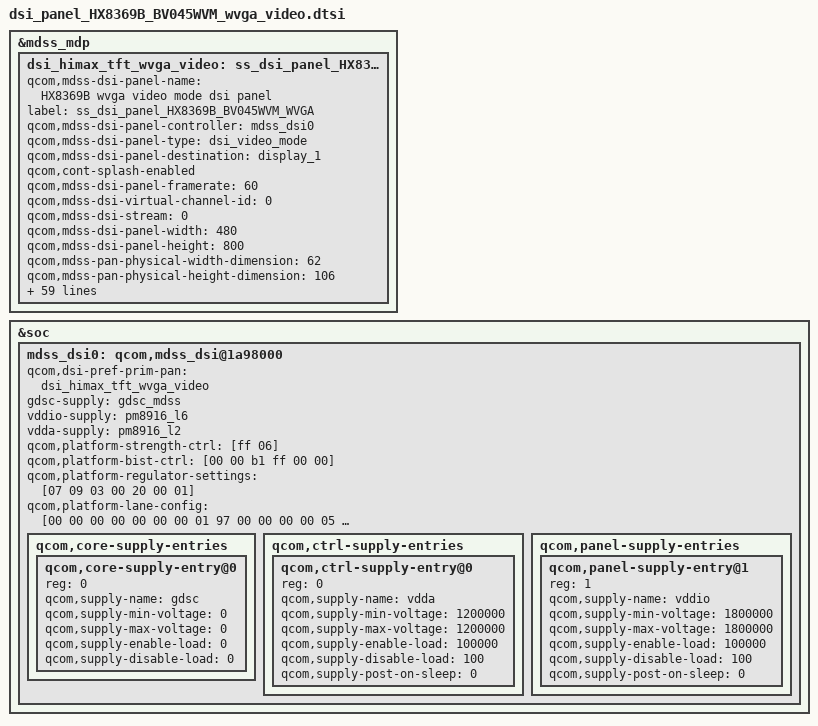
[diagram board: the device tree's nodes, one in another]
/* Copyright (c) 2013-14, Samsung Electronics Corporation. All rights reserved.
 *
 * This program is free software; you can redistribute it and/or modify
 * it under the terms of the GNU General Public License version 2 and
 * only version 2 as published by the Free Software Foundation.
 *
 * This program is distributed in the hope that it will be useful,
 * but WITHOUT ANY WARRANTY; without even the implied warranty of
 * MERCHANTABILITY or FITNESS FOR A PARTICULAR PURPOSE.  See the
 * GNU General Public License for more details.
 */

/*---------------------------------------------------------------------------
 * This file is autogenerated file using gcdb parser. Please do not edit it.
 * Update input XML file to add a new entry or update variable in this file
 * VERSION = "1.0"
 *---------------------------------------------------------------------------*/
&mdss_mdp {
	dsi_himax_tft_wvga_video: ss_dsi_panel_HX8369B_BV045WVM_WVGA/*qcom,mdss_dsi_hx8369b_wvga_video*/ {
		qcom,mdss-dsi-panel-name = "HX8369B wvga video mode dsi panel";
		label = "ss_dsi_panel_HX8369B_BV045WVM_WVGA";
		qcom,mdss-dsi-panel-controller = <&mdss_dsi0>;
		qcom,mdss-dsi-panel-type = "dsi_video_mode";
		qcom,mdss-dsi-panel-destination = "display_1";
		qcom,cont-splash-enabled;
		qcom,mdss-dsi-panel-framerate = <60>;
		qcom,mdss-dsi-virtual-channel-id = <0>;
		qcom,mdss-dsi-stream = <0>;
		qcom,mdss-dsi-panel-width = <480>;
		qcom,mdss-dsi-panel-height = <800>;
		qcom,mdss-pan-physical-width-dimension = <62>; /* <Width> real size of panel in mm */
		qcom,mdss-pan-physical-height-dimension = <106>; /*<Height> real size of panel in mm */
		qcom,mdss-dsi-lp11-init;
		qcom,mdss-dsi-init-delay-us = <100>;
		qcom,mdss-dsi-h-front-porch = <110>;
		qcom,mdss-dsi-h-back-porch = <110>;
		qcom,mdss-dsi-h-pulse-width = <4>;
		qcom,mdss-dsi-h-sync-skew = <0>;
		qcom,mdss-dsi-v-back-porch = <12>;
		qcom,mdss-dsi-v-front-porch = <10>;
		qcom,mdss-dsi-v-pulse-width = <4>;
		qcom,mdss-dsi-h-left-border = <0>;
		qcom,mdss-dsi-h-right-border = <0>;
		qcom,mdss-dsi-v-top-border = <0>;
		qcom,mdss-dsi-v-bottom-border = <0>;
		qcom,mdss-dsi-bpp = <24>;
		qcom,mdss-dsi-color-order = <0>;
		qcom,mdss-dsi-underflow-color = <0xff>;
		qcom,mdss-dsi-border-color = <0>;
		qcom,mdss-dsi-dma-trigger = "trigger_sw";
		qcom,mdss-dsi-mdp-trigger = "none";
		qcom,mdss-dsi-bl-min-level = <1>;
		qcom,mdss-dsi-bl-max-level = <255>;
		qcom,mdss-dsi-bl-pmic-control-type = "bl_ctrl_dcs";
		qcom,mdss-dsi-lane-0-state;
		qcom,mdss-dsi-lane-1-state;
		qcom,mdss-dsi-bllp-eof-power-mode;
		qcom,mdss-dsi-bllp-power-mode;
		qcom,mdss-dsi-traffic-mode = "burst_mode";
		qcom,mdss-force-clk-lane-hs = <0>;
		qcom,mdss-dsi-reset-sequence = <1 20>, <0 1>, <1 20>;
		qcom,mdss-dsi-h-sync-pulse = <0>;
		qcom,mdss-dsi-panel-timings = [51 14 0C 00 36 38 12 18 1B 03 04 00];
		qcom,mdss-dsi-t-clk-pre = <0x15>;
		qcom,mdss-dsi-t-clk-post = <0x04>;
		qcom,mdss-dsi-on-command = [
					/* < Power Setting Sequence(1) > */
					39 01 00 00 00 00 04 B9 FF 83 69
					39 01 00 00 00 00 0B B1 0B 83 77 00 0F 0F 0B 0B 0C 0A
					39 01 00 00 00 00 04 C6 41 FF 7D
					39 01 00 00 00 00 05 E3 00 00 00 00
					39 01 00 00 00 00 07 C0 73 50 00 34 C4 00
					/* < Power Setting Sequence(2) > */
					39 01 00 00 00 00 10 BA 31 00 16 CA B1 0A 00 10 28 02 21 21 9A 1A 8F
					39 01 00 00 00 00 02 3A 70
					39 01 00 00 00 00 05 B3 83 00 31 03
					39 01 00 00 00 00 02 B4 00
					39 01 00 00 00 00 02 CC 0E
					39 01 00 00 00 00 02 EA 72
					39 01 00 00 00 00 02 B2 03
					39 01 00 00 00 00 5D D5 00 00 07 00 09 00 00 10 01 00 00 00 01 42 37
										 00 00 08 2A 08 47 00 00 03 00 00 00 00 00 00 00
										 00 00 00 00 15 00 00 98 98 44 66 00 22 51 00 00
										 89 98 33 11 77 55 04 00 00 98 98 55 77 11 33 40
										 00 00 89 98 22 00 66 44 15 00 00 00 01 00 00 00
										 03 00 0F FF FF 03 00 0F FF FF 00 8C 5A
					/* < Gamma Setting Sequence(3) > */
					39 01 00 00 00 00 24 E0 01 02 05 2C 33 3F 10 33 06 0D 0E 10 16 10 14
										 13 19 01 02 05 2C 32 3F 0E 30 08 0E 0F 12 11 14
										 12 13 19 01
					/* < Display on Sequence> */
					39 01 00 00 00 00 03 C9 0F 01
					39 01 00 00 00 00 02 55 00
					39 01 00 00 00 00 02 53 24
					05 01 00 00 78 00 02 11 00
					05 01 00 00 0A 00 02 29 00
					];
		qcom,mdss-dsi-on-command-state = "dsi_lp_mode";
		qcom,mdss-dsi-off-command-state = "dsi_hs_mode";
		qcom,mdss-dsi-off-command = [39 01 00 00 46 00 02 28 00
					39 01 00 00 46 00 02 10 00];
		samsung,tft-common-support;
		samsung,panel-vendor = "BOE";
		samsung,mdss-dsi-bl-scale-low-level = <8>;
		samsung,mdss-dsi-bl-scale-dim-level = <8>;
		samsung,mdss-dsi-bl-scale-default-level = <89>;
		samsung,mdss-dsi-bl-scale-max-level = <188>;
		samsung,mdss-dsi-bl-pms-low-level = <7>;
		samsung,mdss-dsi-bl-pms-dim-level = <7>;
		samsung,mdss-dsi-bl-pms-default-level = <158>;
		samsung,mdss-dsi-bl-pms-max-level = <255>;
		samsung,tft_pwm_tx_cmds_revA=[
			39 01 00 00 00 00 02 51 FF/*First command should be PWM duty change command*/
		];
		samsung,cabc_on_tx_cmds_revA = [
			39 01 00 00 00 00 02 55 01
		];
		samsung,cabc_off_tx_cmds_revA = [
			39 01 00 00 00 00 02 55 00
		];
		/*
		* ************************************************************************************************************************
		* Scaled level to index mappings
		* ************************************************************************************************************************
		*/
		samsung,scaled_level_map_table_revA = <
		/*<idx>	  <from>  <till> <scaled_level> */
			0		0		7		6
			1		8		9		7
			2		10		12		8
			3		13		14		9
			4		15		17		10
			5		18		19		11
			6		20		22		12
			7		23		24		13
			8		25		27		14
			9		28		29		15
			10		30		32		16
			11		33		34		17
			12		35		37		18
			13		38		39		19
			14		40		42		20
			15		43		44		21
			16		45		47		22
			17		48		49		23
			18		50		52		24
			19		53		54		25
			20		55		57		26
			21		58		59		27
			22		60		62		28
			23		63		64		29
			24		65		67		30
			25		68		70		31
			26		71		72		32
			27		73		75		33
			28		76		77		34
			29		78		80		35
			30		81		82		36
			31		83		85		37
			32		86		87		38
			33		88		90		39
			34		91		92		41
			35		93		95		43
			36		96		97		45
			37		98		100		47
			38		101		102		49
			39		103		105		51
			40		106		107		53
			41		108		110		55
			42		111		112		57
			43		113		115		59
			44		116		117		61
			45		118		120		63
			46		121		122		65
			47		123		125		67
			48		126		127		69
			49		128		130		71
			50		131		133		73
			51		134		135		75
			52		136		138		77
			53		139		140		79
			54		141		143		81
			55		144		145		83
			56		146		148		85
			57		149		150		87
			58		151		153		89
			59		154		155		91
			60		156		158		93
			61		159		160		95
			62		161		163		98
			63		164		165		101
			64		166		168		104
			65		169		170		107
			66		171		173		110
			67		174		175		113
			68		176		178		116
			69		179		180		119
			70		181		183		122
			71		184		185		125
			72		186		188		128
			72		189		190		131
			74		191		193		134
			75		194		196		137
			76		197		198		140
			77		199		201		143
			78		202		203		146
			79		204		206		149
			80		207		208		152
			81		209		211		155
			82		212		213		158
			83		214		216		161
			84		217		218		164
			85		219		221		167
			86		222		223		170
			87		224		226		173
			88		227		228		176
			89		229		231		179
			90		232		233		182
			91		234		236		185
			92		237		238		188
			93		239		241		191
			94		242		243		195
			95		244		246		199
			96		247		248		202
			97		249		251		205
			98		252		253		208
			99		254		255		210
		>;
	};
};
&soc {
	mdss_dsi0: qcom,mdss_dsi@1a98000 {
		qcom,dsi-pref-prim-pan = <&dsi_himax_tft_wvga_video>;
		gdsc-supply = <&gdsc_mdss>;
		vddio-supply = <&pm8916_l6>;
		vdda-supply = <&pm8916_l2>;
		qcom,platform-strength-ctrl = [ff 06];
		qcom,platform-bist-ctrl = [00 00 b1 ff 00 00];
		qcom,platform-regulator-settings = [07 09 03 00 20 00 01];
		qcom,platform-lane-config = [00 00 00 00 00 00 00 01 97
			00 00 00 00 05 00 00 01 97
			00 00 00 00 0a 00 00 01 97
			00 00 00 00 0f 00 00 01 97
			00 c0 00 00 00 00 00 01 bb];
		qcom,core-supply-entries {
			#address-cells = <1>;
			#size-cells = <0>;

			qcom,core-supply-entry@0 {
				reg = <0>;
				qcom,supply-name = "gdsc";
				qcom,supply-min-voltage = <0>;
				qcom,supply-max-voltage = <0>;
				qcom,supply-enable-load = <0>;
				qcom,supply-disable-load = <0>;
			};
		};
		qcom,ctrl-supply-entries {
			#address-cells = <1>;
			#size-cells = <0>;

			qcom,ctrl-supply-entry@0 {
				reg = <0>;
				qcom,supply-name = "vdda";
				qcom,supply-min-voltage = <1200000>;
				qcom,supply-max-voltage = <1200000>;
				qcom,supply-enable-load = <100000>;
				qcom,supply-disable-load = <100>;
				qcom,supply-post-on-sleep = <0>;
			};
		};
		qcom,panel-supply-entries {
			#address-cells = <1>;
			#size-cells = <0>;

			qcom,panel-supply-entry@1 {
				reg = <1>;
				qcom,supply-name = "vddio";
				qcom,supply-min-voltage = <1800000>;
				qcom,supply-max-voltage = <1800000>;
				qcom,supply-enable-load = <100000>;
				qcom,supply-disable-load = <100>;
				qcom,supply-post-on-sleep = <0>;
			};
		};
	};
};

